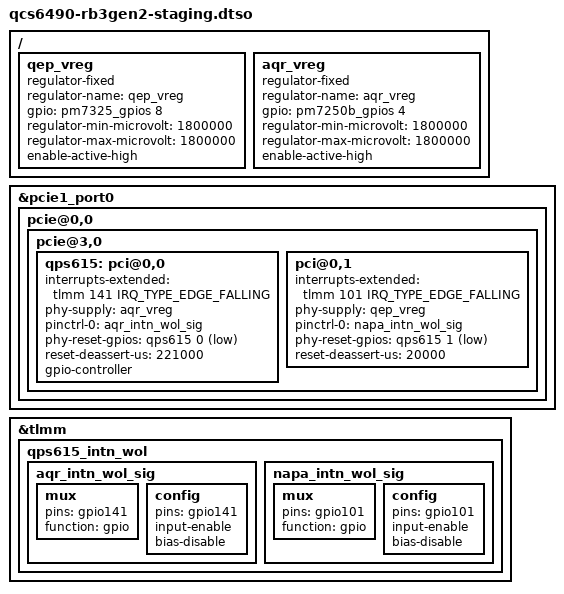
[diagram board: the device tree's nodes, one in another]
// SPDX-License-Identifier: BSD-3-Clause
/*
 * Copyright (c) Qualcomm Technologies, Inc. and/or its subsidiaries.
 */

/dts-v1/;
/plugin/;

#include <dt-bindings/gpio/gpio.h>
#include <dt-bindings/interrupt-controller/irq.h>

/ {
	qep_vreg: qep_vreg {
		compatible = "regulator-fixed";
		regulator-name = "qep_vreg";
		gpio = <&pm7325_gpios 8 0>;
		regulator-min-microvolt = <1800000>;
		regulator-max-microvolt = <1800000>;
		enable-active-high;
	};

	aqr_vreg: aqr_vreg {
		compatible = "regulator-fixed";
		regulator-name = "aqr_vreg";
		gpio = <&pm7250b_gpios 4 0>;
		regulator-min-microvolt = <1800000>;
		regulator-max-microvolt = <1800000>;
		enable-active-high;
	};
};

&pcie1_port0 {
	pcie@0,0 {
		pcie@3,0 {
			/*
			 * PF0: also acts as the QPS615 GPIO controller.
			 * gpio-controller / #gpio-cells expose the TC956X
			 * internal GPIO lines (hardware numbers 0-13) so that
			 * phy-reset-gpios can reference them.
			 */
			qps615: pci@0,0 {
				interrupts-extended = <&tlmm 141 IRQ_TYPE_EDGE_FALLING>;
				interrupt-names = "wol_irq";
				phy-supply = <&aqr_vreg>;
				pinctrl-names = "default";
				pinctrl-0 = <&aqr_intn_wol_sig>;
				phy-reset-gpios = <&qps615 0 GPIO_ACTIVE_LOW>;
				reset-deassert-us = <221000>;

				gpio-controller;
				#gpio-cells = <2>;
			};

			pci@0,1 {
				interrupts-extended = <&tlmm 101 IRQ_TYPE_EDGE_FALLING>;
				interrupt-names = "wol_irq";
				phy-supply = <&qep_vreg>;
				pinctrl-names = "default";
				pinctrl-0 = <&napa_intn_wol_sig>;
				phy-reset-gpios = <&qps615 1 GPIO_ACTIVE_LOW>;
				reset-deassert-us = <20000>;
			};
		};
	};
};

&tlmm {
	qps615_intn_wol {
		aqr_intn_wol_sig: aqr_intn_wol_sig {
			mux {
				pins = "gpio141";
				function = "gpio";
			};

			config {
				pins = "gpio141";
				input-enable;
				bias-disable;
			};
		};

		napa_intn_wol_sig: napa_intn_wol_sig {
			mux {
				pins = "gpio101";
				function = "gpio";
			};

			config {
				pins = "gpio101";
				input-enable;
				bias-disable;
			};
		};
	};
};
